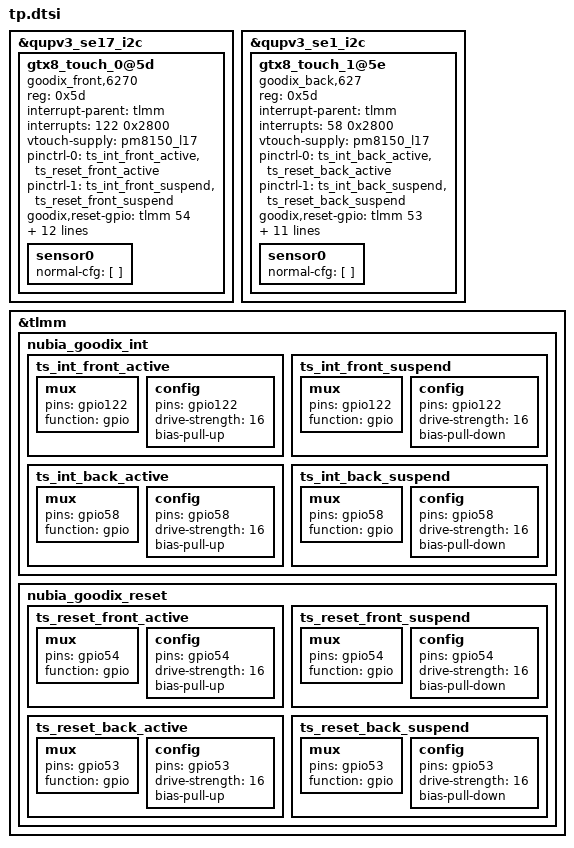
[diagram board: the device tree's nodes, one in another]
/*
 * Copyright (c) 2015-2016, The Linux Foundation. All rights reserved.
 *
 * This program is free software; you can redistribute it and/or modify
 * it under the terms of the GNU General Public License version 2 and
 * only version 2 as published by the Free Software Foundation.
 *
 * This program is distributed in the hope that it will be useful,
 * but WITHOUT ANY WARRANTY; without even the implied warranty of
 * MERCHANTABILITY or FITNESS FOR A PARTICULAR PURPOSE.  See the
 * GNU General Public License for more details.
 */


&qupv3_se17_i2c {
	status = "ok";
		gtx8_touch_0@5d {
			compatible = "goodix_front,6270";
			reg = <0x5d>;
			status = "ok";
			interrupt-parent = <&tlmm>;
			interrupts = <122 0x2800>;
			vtouch-supply = <&pm8150_l17>;
			pinctrl-names = "pmx_ts_front_active","pmx_ts_front_suspend";
			pinctrl-0 = <&ts_int_front_active &ts_reset_front_active>;
			pinctrl-1 = <&ts_int_front_suspend &ts_reset_front_suspend>;
			goodix,reset-gpio = <&tlmm 54 0x0>;
			goodix,power-gpio = <&tlmm 37 0x0>;
			goodix,irq-gpio = <&tlmm 122 0x2800>;
			goodix,irq-flags = <2>; 
			goodix,panel-max-id = <10>;
			goodix,panel-max-x = <1080>;
			goodix,panel-max-y = <2340>;
			goodix,panel-max-w = <512>;
			goodix,panel-max-p = <512>;
			goodix,power-on-delay-us = <300000>; 
			goodix,power-off-delay-us = <5000>;
			goodix,pen-enable;
			goodix,key-of-pen = <331 332>;
			sensor0 {
				normal-cfg = [
					];
			};
		};
};
&qupv3_se1_i2c {
	status = "ok";
		gtx8_touch_1@5e {
			compatible = "goodix_back,627";
			reg = <0x5d>;
			status = "ok";
			interrupt-parent = <&tlmm>;
			interrupts = <58 0x2800>;
			vtouch-supply = <&pm8150_l17>;
			pinctrl-names = "pmx_ts_back_active","pmx_ts_back_suspend";
			pinctrl-0 = <&ts_int_back_active &ts_reset_back_active>;
			pinctrl-1 = <&ts_int_back_suspend &ts_reset_back_suspend>;
			goodix,reset-gpio = <&tlmm 53 0x0>;
			goodix,irq-gpio = <&tlmm 58 0x2800>;
			goodix,irq-flags = <2>; 
			goodix,panel-max-id = <10>;
			goodix,panel-max-x = <720>;
			goodix,panel-max-y = <1520>;
			goodix,panel-max-w = <512>;
			goodix,panel-max-p = <512>;
			goodix,power-on-delay-us = <300000>; 
			goodix,power-off-delay-us = <5000>;
			goodix,pen-enable;
			goodix,key-of-pen = <331 332>;
			sensor0 {
				normal-cfg = [
					];
			};
		};
};


&tlmm {
	//nubia front touch screen
	//nubia back touch screen pinctrl
	nubia_goodix_int {
ts_int_front_active: ts_int_front_active {
		       mux {
			       pins = "gpio122";
			       function = "gpio";
		       };
		       config {
			       pins = "gpio122";
			       drive-strength = <16>;
			       bias-pull-up;
		       };
	       };
ts_int_front_suspend: ts_int_front_suspend {
			mux {
				pins = "gpio122";
				function = "gpio";
			};
			config {
				pins = "gpio122";
				drive-strength = <16>;
				bias-pull-down;
			};
		};
	
	
ts_int_back_active: ts_int_back_active {
		       mux {
			       pins = "gpio58";
			       function = "gpio";
		       };
		       config {
			       pins = "gpio58";
			       drive-strength = <16>;
			       bias-pull-up;
		       };
	       };
ts_int_back_suspend: ts_int_back_suspend {
			mux {
				pins = "gpio58";
				function = "gpio";
			};
			config {
				pins = "gpio58";
				drive-strength = <16>;
				bias-pull-down;
			};
		};
	};
	//nubia touch screen pinctrl
	nubia_goodix_reset {
ts_reset_front_active: ts_reset_front_active {
			 mux {
				 pins = "gpio54";
				 function = "gpio";
			 };
			 config {
				 pins = "gpio54";
				 drive-strength = <16>;
				 bias-pull-up;
			 };
		 };
ts_reset_front_suspend: ts_reset_front_suspend {
			  mux {
				  pins = "gpio54";
				  function = "gpio";
			  };
			  config {
				  pins = "gpio54";
				  drive-strength = <16>;
				  bias-pull-down;
			  };
		  };
		  
ts_reset_back_active: ts_reset_back_active {
			 mux {
				 pins = "gpio53";
				 function = "gpio";
			 };
			 config {
				 pins = "gpio53";
				 drive-strength = <16>;
				 bias-pull-up;
			 };
		 };
ts_reset_back_suspend: ts_reset_back_suspend {
			  mux {
				  pins = "gpio53";
				  function = "gpio";
			  };
			  config {
				  pins = "gpio53";
				  drive-strength = <16>;
				  bias-pull-down;
			  };
		  };
	};
};
